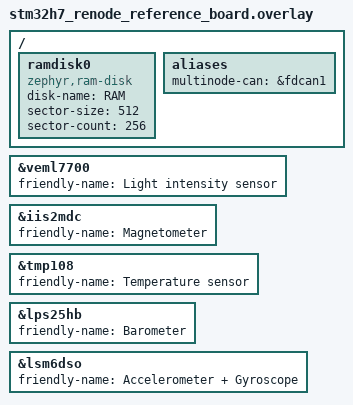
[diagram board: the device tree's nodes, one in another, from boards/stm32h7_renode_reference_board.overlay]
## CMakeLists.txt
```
# Copyright (c) 2026 Antmicro <www.antmicro.com>
# SPDX-License-Identifier: Apache-2.0

cmake_minimum_required(VERSION 3.20)
find_package(Zephyr REQUIRED HINTS $ENV{ZEPHYR_BASE})

project(renode_demo LANGUAGES C)

target_sources(app PRIVATE src/potentiometer.c src/flash_store.c)

target_sources_ifdef(CONFIG_DEMO_USB app PRIVATE src/usbdev.c)
target_sources_ifdef(CONFIG_DEMO_MULTINODE app PRIVATE src/multinode.c)
target_sources_ifdef(CONFIG_DEMO_MULTINODE_ETH app PRIVATE src/multinode_eth.c)
target_sources_ifdef(CONFIG_DEMO_MULTINODE_CAN app PRIVATE src/multinode_can.c)
```

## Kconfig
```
# Copyright (c) 2026 Antmicro <www.antmicro.com>
# SPDX-License-Identifier: Apache-2.0

menu "Demo options"

config DEMO_FLASH_STORE_MSG_BUF_SIZE
	int "Maximum flash_store message size"
	default 128
	help
	  Maximum size of custom message saved to flash storage.

config DEMO_USB
	bool "USB device shell"
	select USB_DEVICE_STACK_NEXT
	select USBD_MSC_CLASS
	help
	  Enable USB device shell.

if DEMO_USB

if LOG

choice USBD_LOG_LEVEL_CHOICE
	default USBD_LOG_LEVEL_WRN

endchoice

choice USBD_MSC_LOG_LEVEL_CHOICE
	default USBD_MSC_LOG_LEVEL_OFF

endchoice

endif # LOG

config DEMO_USB_MAX_POWER
	int "USB device bMaxPower value"
	default 125
	range 0 250
	help
	  bMaxPower value in the usb device configuration in 2 mA units.

endif # DEMO_USB

config DEMO_MULTINODE
	bool "Multinode demo shell"
	default y
	help
	  Enable multinode demo shell.

if DEMO_MULTINODE

config DEMO_MULTINODE_ETH
	bool "Ethernet backend"
	default y
	select NETWORKING
	select NET_IPV4
	select NET_UDP
	select NET_SOCKETS
	select NET_L2_ETHERNET
	help
	  Enable ethernet backend.

if DEMO_MULTINODE_ETH

menu "Network options"

config DEMO_MULTINODE_ETH_SERVER_IP
	string "Server IP"
	default "10.123.123.1"
	help
	  IPv4 address for server node.

config DEMO_MULTINODE_ETH_SERVER_PORT
	int "Server port"
	range 1 65535
	default 4242
	help
	  Port number for the server.

config DEMO_MULTINODE_ETH_CLIENT_IP
	string "Client IP"
	default "10.123.123.2"
	help
	  IPv4 address for client node.

config DEMO_MULTINODE_ETH_NETMASK
	string "Network mask"
	default "255.255.255.0"
	help
	  Network mask for client and server.

config DEMO_MULTINODE_ETH_LINK_TIMEOUT
	int "Link wait time"
	default 10000
	help
	  How long to wait for link to be up before timing out (in ms).

config DEMO_MULTINODE_ETH_RX_TIMEOUT
	int "Response timeout"
	default 1000
	help
	  How long to wait for response (in ms).

config DEMO_MULTINODE_ETH_RX_BUF_SIZE
	int "RX buffer size"
	default 64
	help
	  Rx buffer size (in bytes).

config DEMO_MULTINODE_ETH_TX_BUF_SIZE
	int "TX buffer size"
	default 64
	help
	  Tx buffer size (in bytes).

endmenu

config DEMO_MULTINODE_ETH_SERVER_THRD_STACK_SIZE
	int "Server thread stack size"
	default 2048

config DEMO_MULTINODE_ETH_SERVER_THRD_PRIO
	int "Server thread priority"
	default 5

endif # DEMO_MULTINODE_ETH

config DEMO_MULTINODE_CAN
	bool "CAN backend"
	default y
	select CAN
	select POLL
	help
	  Enable CAN backend.

if DEMO_MULTINODE_CAN

config DEMO_MULTINODE_CAN_REQ_MSG_ID
	hex "Can Request Message ID"
	default 0x25
	help
	  CAN message ID used by request messages.

config DEMO_MULTINODE_CAN_RESP_MSG_ID
	hex "Can Response Message ID"
	default 0x26
	help
	  CAN message ID used by response messages.

config DEMO_MULTINODE_CAN_RX_QUEUE_SIZE
	int "CAN demo receive queue size"
	default 5
	range 1 256
	help
	  Maximum number of CAN frames in the CAN multinohde demo receive queue.

config DEMO_MULTINODE_CAN_TIMEOUT
	int "Message transfer timeout"
	default 1000
	help
	  How long to wait for messages (in ms).

config DEMO_MULTINODE_CAN_LISTEN_THRD_STACK_SIZE
	int "Listen thread stack size"
	default 512

config DEMO_MULTINODE_CAN_LISTEN_THRD_PRIO
	int "Listen thread priority"
	default 5


endif # DEMO_MULTINODE_CAN

endif # DEMO_MULTINODE

endmenu

source "Kconfig.zephyr"
```

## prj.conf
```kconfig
CONFIG_STD_C23=y
CONFIG_BOOT_BANNER_STRING="Booting STM32H7 Renode Reference Platform Demo"

CONFIG_LOG=y
CONFIG_LOG_PROCESS_THREAD_SLEEP_MS=400
CONFIG_LOG_INFO_COLOR_GREEN=y
CONFIG_LOG_DBG_COLOR_BLUE=y

CONFIG_SHELL=y
CONFIG_SHELL_PROMPT_UART="demo:~$ "

CONFIG_STATS=y

CONFIG_ADC=y

CONFIG_CAN=y
CONFIG_CAN_SHELL=y
CONFIG_CAN_STATS=y

CONFIG_FLASH=y
CONFIG_FLASH_LOG_LEVEL_WRN=y
CONFIG_NVS=y
CONFIG_NVS_LOG_LEVEL_WRN=y
CONFIG_REBOOT=y

CONFIG_NETWORKING=y
CONFIG_NET_SHELL=y
CONFIG_NET_HOSTNAME_ENABLE=y
CONFIG_NET_HOSTNAME_DYNAMIC=y
CONFIG_NET_HOSTNAME="demo"
CONFIG_NET_DHCPV4=y
CONFIG_NET_DHCPV4_SERVER=y
CONFIG_NET_IPV4=y
CONFIG_NET_IPV4_FRAGMENT=y
CONFIG_NET_IPV4_PMTU=y
CONFIG_NET_IPV6=y
CONFIG_NET_BUF_POOL_USAGE=y
CONFIG_NET_STATISTICS=y
CONFIG_NET_SHELL_SHOW_DISABLED_COMMANDS=n

CONFIG_DNS_RESOLVER=y

CONFIG_HWINFO_SHELL=y

CONFIG_I2C=y
CONFIG_I2C_SHELL=y
CONFIG_I2C_BUS_RECOVERY=y

CONFIG_INPUT=y
CONFIG_INPUT_SHELL=y
CONFIG_INPUT_EVENT_DUMP=y

CONFIG_LED=y
CONFIG_LED_SHELL=y

CONFIG_SENSOR=y
CONFIG_SENSOR_SHELL=y
CONFIG_SENSOR_INFO=y
CONFIG_MAIN_STACK_SIZE=2048
CONFIG_SYSTEM_WORKQUEUE_STACK_SIZE=2048
```

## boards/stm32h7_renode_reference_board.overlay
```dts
/ {
	// 128KB ramdisk
	ramdisk0 {
		compatible = "zephyr,ram-disk";
		disk-name = "RAM";
		sector-size = <512>;
		sector-count = <256>;
	};

	aliases {
		multinode-can = &fdcan1;
	};
};

&veml7700 {
	friendly-name = "Light intensity sensor";
};

&iis2mdc {
	friendly-name = "Magnetometer";
};

&tmp108 {
	friendly-name = "Temperature sensor";
};

&lps25hb {
	friendly-name = "Barometer";
};

&lsm6dso {
	friendly-name = "Accelerometer + Gyroscope";
};
```

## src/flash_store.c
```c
/*
 * Copyright (c) 2026 Antmicro <www.antmicro.com>
 * SPDX-License-Identifier: Apache-2.0
 */

#include <stddef.h>
#include <stdint.h>
#include <string.h>
#include <zephyr/kernel.h>
#include <zephyr/device.h>
#include <zephyr/drivers/flash.h>
#include <zephyr/storage/flash_map.h>
#include <zephyr/kvss/nvs.h>
#include <zephyr/shell/shell.h>
#include <zephyr/toolchain.h>
#include <zephyr/sys/util.h>
#include <zephyr/logging/log.h>

LOG_MODULE_REGISTER(flash_store);

#define NVS_PARTITION storage_partition

static struct nvs_fs fs = {
	.flash_device = PARTITION_DEVICE(NVS_PARTITION),
	.offset = PARTITION_OFFSET(NVS_PARTITION),
	.sector_count = 3U,
};

#define DEMO_BOOT_CNT_KEY 1
#define DEMO_MESSAGE_KEY  2

static const char demo_message_default[] = "All your base are belong to us";
static uint8_t buffer[CONFIG_DEMO_FLASH_STORE_MSG_BUF_SIZE] = {0};

static int flash_store_bootcnt_cmd_get(const struct shell *sh, size_t argc, char *argv[]);
static int flash_store_bootcnt_cmd_reset(const struct shell *sh, size_t argc, char *argv[]);
static int flash_store_msg_cmd_read(const struct shell *sh, size_t argc, char *argv[]);
static int flash_store_msg_cmd_write(const struct shell *sh, size_t argc, char *argv[]);

static int bootcnt_write(uint32_t cnt)
{
	int rc;

	LOG_DBG("Setting boot count to %d", cnt);
	rc = nvs_write(&fs, DEMO_BOOT_CNT_KEY, (void *)&cnt, sizeof(cnt));
	if (rc < 0) {
		return rc;
	}

	return 0;
}

static int message_write(const char *str)
{
	int rc;
	size_t msg_len = strlen(str);

	/* Truncate string to fit in buffer */
	msg_len = MIN(msg_len, sizeof(buffer) - 1);
	memcpy(buffer, str, msg_len);
	buffer[msg_len++] = 0;

	LOG_DBG("Writing %d bytes long message to flash", msg_len);

	rc = nvs_write(&fs, DEMO_MESSAGE_KEY, (void *)buffer, msg_len);
	if (rc < 0) {
	}
	return rc;
}

static int demo_flash_init(void)
{
	int rc;
	uint32_t boot_cnt;
	struct flash_pages_info info;

	if (!device_is_ready(fs.flash_device)) {
		LOG_ERR("Flash device %s is not ready", fs.flash_device->name);
		return -ENODEV;
	}

	LOG_DBG("Using flash device '%s' at offset %ld", fs.flash_device->name, fs.offset);

	rc = flash_get_page_info_by_offs(fs.flash_device, fs.offset, &info);
	if (rc) {
		LOG_ERR("Unable to get page info (err=%d)", rc);
		return rc;
	}
	fs.sector_size = info.size;

	LOG_DBG("Page Info - start offset: %ld, size: %zu, index: %d", info.start_offset, info.size,
		info.index);

	rc = nvs_mount(&fs);
	if (rc) {
		LOG_ERR("Failed to mount flash storage (err=%d)", rc);
		return rc;
	}

	/* Check if first boot and set default values if so */
	rc = nvs_read(&fs, DEMO_BOOT_CNT_KEY, (void *)&boot_cnt, sizeof(boot_cnt));
	if (rc > 0) {
		LOG_DBG("Boot counter at %d, incrementing to %d", boot_cnt, boot_cnt + 1);
		++boot_cnt;
	} else {
		LOG_DBG("Boot counter not found, setting to default value");
		boot_cnt = 1;
	}
	rc = bootcnt_write(boot_cnt);
	if (rc < 0) {
		LOG_ERR("Failed to write boot count to flash (err=%d)", rc);
		return rc;
	}

	rc = nvs_read(&fs, DEMO_MESSAGE_KEY, (void *)buffer, sizeof(buffer));
	if (rc <= 0) {
		LOG_DBG("Custom message not found, setting to default value");
		rc = message_write(demo_message_default);
		if (rc < 0) {
			LOG_ERR("Failed to write message to flash (err=%d)", rc);
			return rc;
		}
	}

	return 0;
}

SYS_INIT(demo_flash_init, APPLICATION, 0);

SHELL_STATIC_SUBCMD_SET_CREATE(flash_store_bootcnt_cmds,
			       SHELL_CMD_ARG(get, NULL, SHELL_HELP("Get boot counter.", ""),
					     flash_store_bootcnt_cmd_get, 1, 0),
			       SHELL_CMD_ARG(reset, NULL, SHELL_HELP("Reset boot counter.", ""),
					     flash_store_bootcnt_cmd_reset, 1, 0),
			       SHELL_SUBCMD_SET_END);

static int flash_store_bootcnt_cmd_get(const struct shell *sh, size_t argc, char *argv[])
{
	ARG_UNUSED(argc);
	ARG_UNUSED(argv);

	int rc;
	uint32_t boot_cnt;

	rc = nvs_read(&fs, DEMO_BOOT_CNT_KEY, (void *)&boot_cnt, sizeof(boot_cnt));
	if (rc < 0) {
		shell_error(sh, "Reading boot counter failed (err=%d)", rc);
		return rc;
	}

	shell_print(sh, "Boot counter = %d", boot_cnt);
	return 0;
}

static int flash_store_bootcnt_cmd_reset(const struct shell *sh, size_t argc, char *argv[])
{
	ARG_UNUSED(argc);
	ARG_UNUSED(argv);

	int rc;

	rc = bootcnt_write(0);
	if (rc < 0) {
		shell_error(sh, "Failed to reset boot counter (err=%d)", rc);
		return rc;
	}
	shell_info(sh, "Boot counter reset");
	return 0;
}

SHELL_STATIC_SUBCMD_SET_CREATE(flash_store_message_cmds,
			       SHELL_CMD_ARG(read, NULL, SHELL_HELP("Read saved message.", ""),
					     flash_store_msg_cmd_read, 1, 0),
			       SHELL_CMD_ARG(write, NULL,
					     SHELL_HELP("Write new message.", "MESSAGE"),
					     flash_store_msg_cmd_write, 2, SHELL_OPT_ARG_RAW),
			       SHELL_SUBCMD_SET_END);

static int flash_store_msg_cmd_read(const struct shell *sh, size_t argc, char *argv[])
{
	ARG_UNUSED(argc);
	ARG_UNUSED(argv);

	int rc;

	rc = nvs_read(&fs, DEMO_MESSAGE_KEY, (void *)buffer, sizeof(buffer));
	if (rc < 0) {
		shell_error(sh, "Reading saved message failed (err=%d)", rc);
		return rc;
	}

	shell_print(sh, "Saved message is:\n\"%s\"", buffer);
	return 0;
}

static int flash_store_msg_cmd_write(const struct shell *sh, size_t argc, char *argv[])
{
	ARG_UNUSED(argc);
	ARG_UNUSED(argv);

	int rc;

	rc = message_write(argv[1]);
	if (rc < 0) {
		shell_error(sh, "Writing new message failed (err=%d)", rc);
		return rc;
	}

	shell_info(sh, "New message saved to flash");
	return 0;
}

SHELL_STATIC_SUBCMD_SET_CREATE(flash_store_cmds,
			       SHELL_CMD_ARG(boot_counter, &flash_store_bootcnt_cmds,
					     "Boot counter operations", NULL, 2, 0),
			       SHELL_CMD_ARG(message, &flash_store_message_cmds,
					     "Saved message operations", NULL, 2, 0),
			       SHELL_SUBCMD_SET_END);

SHELL_CMD_REGISTER(flash_store, &flash_store_cmds, "Flash storage commands", NULL);
```

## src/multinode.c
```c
/*
 * Copyright (c) 2026 Antmicro <www.antmicro.com>
 * SPDX-License-Identifier: Apache-2.0
 */

#include "multinode.h"

#include <zephyr/shell/shell.h>

#ifdef CONFIG_DEMO_MULTINODE_ETH
SHELL_STATIC_SUBCMD_SET_CREATE(sub_multinode_eth_server_cmds,
			       SHELL_CMD_ARG(start, nullptr, "Start multinode server",
					     multinode_eth_server_start, 1, 0),
			       SHELL_CMD_ARG(stop, nullptr, "Stop multinode server",
					     multinode_eth_server_stop, 1, 0),
			       SHELL_SUBCMD_SET_END);

SHELL_STATIC_SUBCMD_SET_CREATE(sub_multinode_eth_cmds,
			       SHELL_CMD_ARG(server, &sub_multinode_eth_server_cmds, "Server mode",
					     nullptr, 2, 0),
			       SHELL_CMD_ARG(client, nullptr, "Client mode", multinode_eth_client,
					     1, 0),
			       SHELL_SUBCMD_SET_END);
#endif // CONFIG_DEMO_MULTINODE_ETH

#ifdef CONFIG_DEMO_MULTINODE_CAN
SHELL_STATIC_SUBCMD_SET_CREATE(sub_multinode_can_listen_cmds,
			       SHELL_CMD_ARG(start, nullptr, "Start listening for CAN messages",
					     multinode_can_listen_start, 1, 0),
			       SHELL_CMD_ARG(stop, nullptr, "Stop listening for CAN messages",
					     multinode_can_listen_stop, 1, 0),
			       SHELL_SUBCMD_SET_END);

SHELL_STATIC_SUBCMD_SET_CREATE(sub_multinode_can_cmds,
			       SHELL_CMD_ARG(listen, &sub_multinode_can_listen_cmds, "Listen mode",
					     nullptr, 2, 0),
			       SHELL_CMD_ARG(send, nullptr, "Send mode", multinode_can_send, 1, 0),
			       SHELL_SUBCMD_SET_END);
#endif // CONFIG_DEMO_MULTINODE_CAN

SHELL_STATIC_SUBCMD_SET_CREATE(sub_multinode_cmds,
#ifdef CONFIG_DEMO_MULTINODE_ETH
			       SHELL_CMD_ARG(eth, &sub_multinode_eth_cmds,
					     "Multinode demo over ethernet", nullptr, 1, 0),
#endif // CONFIG_DEMO_MULTINODE_ETH
#ifdef CONFIG_DEMO_MULTINODE_CAN
			       SHELL_CMD_ARG(can, &sub_multinode_can_cmds,
					     "Multinode demo over CAN", nullptr, 1, 0),
#endif // CONFIG_DEMO_MULTINODE_CAN
			       SHELL_SUBCMD_SET_END);

SHELL_CMD_REGISTER(multinode, &sub_multinode_cmds, "Multinode demo commands", NULL);
```

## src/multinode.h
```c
/*
 * Copyright (c) 2026 Antmicro <www.antmicro.com>
 * SPDX-License-Identifier: Apache-2.0
 */

#ifndef _MULTINODE_H
#define _MULTINODE_H

#include <zephyr/shell/shell.h>

#ifdef CONFIG_DEMO_MULTINODE_ETH
int multinode_eth_server_start(const struct shell *sh, size_t argc, char *argv[]);
int multinode_eth_server_stop(const struct shell *sh, size_t argc, char *argv[]);
int multinode_eth_client(const struct shell *sh, size_t argc, char *argv[]);
#endif // CONFIG_DEMO_MULTINODE_ETH

#ifdef CONFIG_DEMO_MULTINODE_CAN
int multinode_can_listen_start(const struct shell *sh, size_t argc, char *argv[]);
int multinode_can_listen_stop(const struct shell *sh, size_t argc, char *argv[]);
int multinode_can_send(const struct shell *sh, size_t argc, char *argv[]);
#endif // CONFIG_DEMO_MULTINODE_CAN

#endif // _MULTINODE_H
```

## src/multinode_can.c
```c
/*
 * Copyright (c) 2026 Antmicro <www.antmicro.com>
 * SPDX-License-Identifier: Apache-2.0
 */

#include "multinode.h"

#include <stdint.h>
#include <string.h>

#include <zephyr/device.h>
#include <zephyr/devicetree.h>
#include <zephyr/devicetree/can.h>
#include <zephyr/drivers/can.h>
#include <zephyr/kernel.h>
#include <zephyr/logging/log.h>
#include <zephyr/shell/shell.h>
#include <zephyr/sys/atomic.h>
#include <zephyr/sys/util.h>
#include <zephyr/sys/util_macro.h>
#include <zephyr/toolchain.h>

LOG_MODULE_REGISTER(multinode_can);

BUILD_ASSERT(CONFIG_DEMO_MULTINODE_CAN_REQ_MSG_ID <= CAN_STD_ID_MASK, "CAN filter ID out of range");
BUILD_ASSERT(CONFIG_DEMO_MULTINODE_CAN_RESP_MSG_ID <= CAN_STD_ID_MASK,
	     "CAN filter ID out of range");

#define CAN_DEVICE DT_ALIAS(multinode_can)

const static struct device *dev = DEVICE_DT_GET(CAN_DEVICE);

const static uint32_t max_bitrate = DT_CAN_TRANSCEIVER_MAX_BITRATE(CAN_DEVICE, 1000000);

const static struct can_filter req_filter = {
	.id = CONFIG_DEMO_MULTINODE_CAN_REQ_MSG_ID,
	.mask = CAN_STD_ID_MASK,
	.flags = 0,
};
static int req_filter_id = -1;
CAN_MSGQ_DEFINE(req_msgq, CONFIG_DEMO_MULTINODE_CAN_RX_QUEUE_SIZE);

const static struct can_filter resp_filter = {
	.id = CONFIG_DEMO_MULTINODE_CAN_RESP_MSG_ID,
	.mask = CAN_STD_ID_MASK,
	.flags = 0,
};
static int resp_filter_id = -1;
CAN_MSGQ_DEFINE(resp_msgq, CONFIG_DEMO_MULTINODE_CAN_RX_QUEUE_SIZE);

#define CAN_CONFIGURED  0
#define CAN_LISTENER_ON 1
#define CAN_SENDER_ON   2

// NOTE: This value is only changed inside shell command handlers (shell thread) so we don't
// have to worry about races.
static int can_state = 0;

static int can_setup(const struct shell *sh)
{
	int rc;

	if (IS_BIT_SET(can_state, CAN_CONFIGURED)) {
		return -EALREADY;
	}

	if (!device_is_ready(dev)) {
		shell_error(sh, "Can device %s not ready", dev->name);
		return -ENODEV;
	}

	LOG_DBG("Setting %s bitrate to %ul", dev->name, max_bitrate);
	rc = can_set_bitrate(dev, max_bitrate);
	if (rc < 0) {
		shell_error(sh, "Failed to set %s device bitrate (err %d)", dev->name, rc);
		return rc;
	}

	LOG_DBG("Setting %s mode to normal", dev->name);
	rc = can_set_mode(dev, CAN_MODE_NORMAL);
	if (rc < 0) {
		shell_error(sh, "Failed to set %s device mode (err %d)", dev->name, rc);
		return rc;
	}

	rc = can_start(dev);
	if (rc < 0) {
		shell_error(sh, "Failed to start %s interface (err %d)", dev->name, rc);
		return rc;
	}

	WRITE_BIT(can_state, CAN_CONFIGURED, 1);
	shell_print(sh, "Configured %s interface", dev->name);

	return rc;
}

static int can_shutdown(const struct shell *sh)
{
	if (!IS_BIT_SET(can_state, CAN_CONFIGURED)) {
		return -EALREADY;
	}
	if (FIELD_GET(GENMASK(CAN_SENDER_ON, CAN_LISTENER_ON), can_state)) {
		return 0;
	}

	can_stop(dev);
	can_state = 0;

	shell_print(sh, "Stopped %s interface", dev->name);

	return 0;
}

static void listener_worker(void *a1, void *a2, void *a3)
{
	ARG_UNUSED(a1);
	ARG_UNUSED(a2);
	ARG_UNUSED(a3);

	struct can_frame rx_frame, tx_frame = {.id = CONFIG_DEMO_MULTINODE_CAN_RESP_MSG_ID,
					       .dlc = can_bytes_to_dlc(sizeof(uint64_t)),
					       .flags = 0};
	int rc;
	for (;;) {
		k_msgq_get(&req_msgq, &rx_frame, K_FOREVER);
		if (can_dlc_to_bytes(rx_frame.dlc) != 8) {
			LOG_ERR("malformed message from %d", rx_frame.id);
			continue;
		}

		LOG_INF("incoming 'Ping%" PRIu64 "'", (uint64_t)(*rx_frame.data));

		memcpy(tx_frame.data, rx_frame.data, 8);
		rc = can_send(dev, &tx_frame, K_MSEC(CONFIG_DEMO_MULTINODE_CAN_TIMEOUT), nullptr,
			      nullptr);

		LOG_INF("response 'Pong%" PRIu64 "'", (uint64_t)(*tx_frame.data));
	}
}
K_THREAD_DEFINE(listener_thrd, CONFIG_DEMO_MULTINODE_CAN_LISTEN_THRD_STACK_SIZE, listener_worker,
		nullptr, nullptr, nullptr, CONFIG_DEMO_MULTINODE_CAN_LISTEN_THRD_PRIO, 0, 0);

static void send_callback(const struct device *dev, int error, void *data)
{
	ARG_UNUSED(dev);

	if (error) {
		return;
	}
	k_sem_give(data);
}

int multinode_can_listen_start(const struct shell *sh, size_t argc, char **argv)
{
	int rc;

	if (IS_BIT_SET(can_state, CAN_LISTENER_ON)) {
		shell_error(sh, "Listener on %s already enabled", dev->name);
		return -EALREADY;
	}

	rc = can_setup(sh);
	if (rc && rc != -EALREADY) {
		return rc;
	}

	LOG_DBG("Enabling request filter");
	req_filter_id = can_add_rx_filter_msgq(dev, &req_msgq, &req_filter);
	if (req_filter_id < 0) {
		shell_error(sh, "Failed to enable request message filter (%d)", req_filter_id);
		return req_filter_id;
	}

	WRITE_BIT(can_state, CAN_LISTENER_ON, 1);
	shell_print(sh, "CAN listener started on %s", dev->name);

	return rc;
}

int multinode_can_listen_stop(const struct shell *sh, size_t argc, char **argv)
{
	int rc;

	if (!IS_BIT_SET(can_state, CAN_LISTENER_ON)) {
		shell_error(sh, "Listener on %s already disabled", dev->name);
		return -EALREADY;
	}

	LOG_DBG("Removing request filter");
	can_remove_rx_filter(dev, req_filter_id);
	req_filter_id = -1;

	WRITE_BIT(can_state, CAN_LISTENER_ON, 0);
	shell_print(sh, "CAN listener stopped on %s", dev->name);

	rc = can_shutdown(sh);
	if (rc && rc != -EALREADY) {
		shell_error(sh, "Interface %s already shutdown", dev->name);
		return rc;
	}

	return rc;
}

int multinode_can_send(const struct shell *sh, size_t argc, char **argv)
{
	int rc;
	int64_t now;
	struct can_frame rx_frame, tx_frame = {.id = CONFIG_DEMO_MULTINODE_CAN_REQ_MSG_ID,
					       .dlc = can_bytes_to_dlc(sizeof(uint64_t)),
					       .flags = 0};
	struct k_sem tx_sem;

	rc = can_setup(sh);

	LOG_DBG("Enabling response filter");
	resp_filter_id = can_add_rx_filter_msgq(dev, &resp_msgq, &resp_filter);
	if (resp_filter_id < 0) {
		shell_error(sh, "Failed to enable response message filter (%d)", resp_filter_id);
		return resp_filter_id;
	}
	WRITE_BIT(can_state, CAN_SENDER_ON, 1);

	k_sem_init(&tx_sem, 0, 1);

	for (uint64_t i = 0; i < 4; ++i) {
		memcpy(tx_frame.data, &i, 8);

		shell_print(sh, "send 'Ping%" PRIu64 "'", i);

		now = k_uptime_get();
		rc = can_send(dev, &tx_frame, K_MSEC(CONFIG_DEMO_MULTINODE_CAN_TIMEOUT),
			      send_callback, &tx_sem);
		if (rc < 0 || (rc = k_sem_take(&tx_sem, K_MSEC(CONFIG_DEMO_MULTINODE_CAN_TIMEOUT -
							       (k_uptime_get() - now))))) {
			shell_error(sh, "Sending message failed (err %d)", rc);
			break;
		}

		rc = k_msgq_get(&resp_msgq, &rx_frame,
				K_MSEC(CONFIG_DEMO_MULTINODE_CAN_TIMEOUT - (k_uptime_get() - now)));
		if (rc < 0) {
			shell_error(sh, "Getting response failed (err=%d)", rc);
			break;
		}

		shell_print(sh, "resp 'Pong%" PRIu64 "' (elapsed %" PRIi64 "ms)",
			    (uint64_t)(*rx_frame.data), k_uptime_delta(&now));

		k_sleep(K_SECONDS(1));
	}

	LOG_DBG("Removing response filter");
	can_remove_rx_filter(dev, resp_filter_id);
	resp_filter_id = -1;

	WRITE_BIT(can_state, CAN_SENDER_ON, 0);
	rc |= can_shutdown(sh);

	return rc;
}
```

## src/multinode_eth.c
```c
/*
 * Copyright (c) 2026 Antmicro <www.antmicro.com>
 * SPDX-License-Identifier: Apache-2.0
 */

#include "multinode.h"

#include <stddef.h>
#include <stdint.h>
#include <stdio.h>
#include <string.h>

#include <zephyr/kernel.h>
#include <zephyr/logging/log.h>
#include <zephyr/net/net_if.h>
#include <zephyr/net/net_ip.h>
#include <zephyr/net/socket.h>
#include <zephyr/net/socket_poll.h>
#include <zephyr/shell/shell.h>
#include <zephyr/sys/atomic.h>
#include <zephyr/sys/util.h>
#include <zephyr/sys/util_macro.h>
#include <zephyr/toolchain.h>

LOG_MODULE_REGISTER(multinode_eth);

#define LINK_UP_TIMEOUT 10000
#define LINK_UP_CHECK   100
#define PING_COUNT      4

#define MAGIC       "MNODE"
#define MSG_HELLO   MAGIC "Hello"
#define MSG_PING    MAGIC "Ping"
#define MSG_PONG    MAGIC "Pong"
#define MSG_GOODBYE MAGIC "Bye"

#define MSG_OFFSET(msg) ((msg) + sizeof(MAGIC) - 1)

static K_TIMER_DEFINE(wait_link_up_timer, NULL, NULL);

static K_SEM_DEFINE(multinode_mode, 1, 1);

static K_EVENT_DEFINE(server_evt);
#define SERVER_EVT_START    BIT(0)
#define SERVER_EVT_RUNNING  BIT(1)
#define SERVER_EVT_STOP     BIT(2)
#define SERVER_EVT_SHUTDOWN BIT(3)

static char recv_buf[CONFIG_DEMO_MULTINODE_ETH_RX_BUF_SIZE];
static char send_buf[CONFIG_DEMO_MULTINODE_ETH_TX_BUF_SIZE];
static char ip_buf[NET_IPV4_ADDR_LEN];
static int sock;

static int wait_link_up(const struct shell *sh, struct net_if *iface)
{
	int steps = 0;

	(void)net_if_up(iface);

	if (net_if_is_up(iface)) {
		return 0;
	}

	shell_fprintf_normal(sh, "Waiting for link up");

	k_timer_start(&wait_link_up_timer, K_MSEC(LINK_UP_TIMEOUT), K_NO_WAIT);
	while (!net_if_is_up(iface)) {
		if (k_timer_status_get(&wait_link_up_timer) > 0) {
			shell_print(sh, " Timeout!");
			return -ETIMEDOUT;
		}

		k_sleep(K_MSEC(LINK_UP_CHECK));
		if (++steps == DIV_ROUND_UP(1000, LINK_UP_CHECK)) {
			shell_fprintf_normal(sh, ".");
			steps = 0;
		}
	}

	shell_print(sh, " done");
	return 0;
}

static int iface_addr_set(const struct shell *sh, const char *ip_str)
{
	struct net_if *iface = net_if_get_default();
	struct net_if *found = nullptr;
	struct in_addr addr, netmask;
	int rc;

	if (iface == nullptr) {
		return -ENODEV;
	}

	rc = wait_link_up(sh, iface);
	if (rc) {
		return rc;
	}

	if (zsock_inet_pton(AF_INET, ip_str, &addr) != 1) {
		return -EINVAL;
	}

	if (net_if_ipv4_addr_lookup(&addr, &found) == nullptr) {
		if (net_if_ipv4_addr_add(iface, &addr, NET_ADDR_MANUAL, 0) == nullptr) {
			return -EADDRNOTAVAIL;
		}
	}

	if (zsock_inet_pton(AF_INET, CONFIG_DEMO_MULTINODE_ETH_NETMASK, &netmask) != 1) {
		return -EINVAL;
	}

	if (!net_if_ipv4_set_netmask_by_addr(iface, &addr, &netmask)) {
		return -EADDRNOTAVAIL;
	}

	return 0;
}

static void iface_addr_rm(const char *ip_str)
{
	struct net_if *iface;
	struct in_addr addr;

	if (zsock_inet_pton(AF_INET, ip_str, &addr) != 1) {
		return;
	}

	if (net_if_ipv4_addr_lookup(&addr, &iface) != nullptr) {
		net_if_ipv4_addr_rm(iface, &addr);
	}
}

static int client_send(int sock, const struct sockaddr_in *const dst, const char *data,
		       size_t data_len, char *recv_buf, size_t recv_size)
{
	struct zsock_pollfd pfd = {.fd = sock, .events = ZSOCK_POLLIN};

	if (zsock_sendto(sock, send_buf, data_len, 0, (struct sockaddr *)dst, sizeof(*dst)) < 0) {
		return -errno;
	}

	if (zsock_poll(&pfd, 1, CONFIG_DEMO_MULTINODE_ETH_RX_TIMEOUT) <= 0) {
		return -ETIMEDOUT;
	}

	data_len = zsock_recv(sock, recv_buf, recv_size, 0);
	if (data_len <= 0) {
		return -EIO;
	}
	recv_buf[data_len] = 0;

	return data_len;
}

static void server_worker(void *a1, void *a2, void *a3)
{
	ARG_UNUSED(a1);
	ARG_UNUSED(a2);
	ARG_UNUSED(a3);

	struct sockaddr_in bind_addr = {.sin_family = AF_INET,
					.sin_addr.s_addr = htonl(INADDR_ANY),
					.sin_port = htons(CONFIG_DEMO_MULTINODE_ETH_SERVER_PORT)};

	/* Start in shutdown */
	k_event_set(&server_evt, SERVER_EVT_SHUTDOWN);

	for (;;) {
		k_event_wait(&server_evt, SERVER_EVT_START, false, K_FOREVER);

		sock = zsock_socket(AF_INET, SOCK_DGRAM, IPPROTO_UDP);
		if (sock < 0) {
			LOG_ERR("socket creation failed (err=%d)", errno);
			k_event_set(&server_evt, SERVER_EVT_SHUTDOWN);
			continue;
		}

		if (zsock_bind(sock, (struct sockaddr *)&bind_addr, sizeof(bind_addr)) < 0) {
			LOG_ERR("binding failed (err=%d)", errno);
			k_event_set(&server_evt, SERVER_EVT_SHUTDOWN);
			continue;
		}

		k_event_set(&server_evt, SERVER_EVT_RUNNING);

		do {
			struct sockaddr_in peer = {0};
			socklen_t peer_len = sizeof(peer);
			struct zsock_pollfd pfd = {
				.fd = sock,
				.events = ZSOCK_POLLIN,
			};
			size_t msg_len;

			if (zsock_poll(&pfd, 1, 500) <= 0) {
				continue;
			}

			msg_len = zsock_recvfrom(sock, recv_buf, sizeof(recv_buf) - 1, 0,
						 (struct sockaddr *)&peer, &peer_len);
			if (msg_len <= 0) {
				continue;
			}

			recv_buf[msg_len] = 0;
			LOG_INF("incoming '%s'", MSG_OFFSET(recv_buf));

			zsock_inet_ntop(AF_INET, &peer.sin_addr, ip_buf, sizeof(ip_buf));

			size_t len = 0;
			if (strncmp(recv_buf, MSG_HELLO, strlen(MSG_HELLO)) == 0) {
				len = snprintf(send_buf, sizeof(send_buf), "%s %s", MSG_HELLO,
					       CONFIG_DEMO_MULTINODE_ETH_SERVER_IP);
			} else if (strncmp(recv_buf, MSG_PING, strlen(MSG_PING)) == 0) {
				len = snprintf(send_buf, sizeof(send_buf), "%s%s", MSG_PONG,
					       MSG_OFFSET(recv_buf) + 4);
			} else if (strncmp(recv_buf, MSG_GOODBYE, strlen(MSG_GOODBYE)) == 0) {
				len = snprintf(send_buf, sizeof(send_buf), "%s %s", MSG_GOODBYE,
					       CONFIG_DEMO_MULTINODE_ETH_SERVER_IP);
			} else {
				LOG_WRN("unknown message format, ignoring");
				continue;
			}
			zsock_sendto(sock, send_buf, len, 0, (struct sockaddr *)&peer, peer_len);
			LOG_INF("response '%s'", MSG_OFFSET(send_buf));

		} while (!k_event_test(&server_evt, SERVER_EVT_STOP));

		zsock_close(sock);
		k_event_set(&server_evt, SERVER_EVT_SHUTDOWN);
	}
}

K_THREAD_DEFINE(server_thrd, CONFIG_DEMO_MULTINODE_ETH_SERVER_THRD_STACK_SIZE, server_worker,
		nullptr, nullptr, nullptr, CONFIG_DEMO_MULTINODE_ETH_SERVER_THRD_PRIO, 0, 0);

int multinode_eth_server_start(const struct shell *sh, size_t argc, char *argv[])
{
	int evt = 0;
	int rc;

	if (k_event_test(&server_evt, SERVER_EVT_START | SERVER_EVT_RUNNING)) {
		shell_error(sh, "Server already running");
		rc = -EINVAL;
		goto _server_cmd_mode_give;
	}

	if (k_sem_take(&multinode_mode, K_NO_WAIT)) {
		shell_error(sh, "Can't run in server and client mode at the same time");
		rc = -ENOTSUP;
		goto _server_cmd_mode_give;
	}

	rc = iface_addr_set(sh, CONFIG_DEMO_MULTINODE_ETH_SERVER_IP);
	if (rc) {
		shell_error(sh, "Failed to setup network interface (err=%d)", rc);
		goto _server_cmd_mode_give;
	}

	k_event_set(&server_evt, SERVER_EVT_START);

	evt = k_event_wait(&server_evt, SERVER_EVT_RUNNING | SERVER_EVT_SHUTDOWN, false, K_FOREVER);
	if (IS_BIT_SET(evt, SERVER_EVT_SHUTDOWN)) {
		shell_error(sh, "Failed to start server");
		rc = -ENODEV;
		goto _server_cmd_mode_give;
	}

	shell_print(sh, "Server started on %s:%d", CONFIG_DEMO_MULTINODE_ETH_SERVER_IP,
		    CONFIG_DEMO_MULTINODE_ETH_SERVER_PORT);

	return 0;

_server_cmd_mode_give:
	k_sem_give(&multinode_mode);

	return rc;
}

int multinode_eth_server_stop(const struct shell *sh, size_t argc, char *argv[])
{
	if (k_event_test(&server_evt, SERVER_EVT_STOP | SERVER_EVT_SHUTDOWN)) {
		shell_error(sh, "Server not running");
		return -EINVAL;
	}

	k_event_set(&server_evt, SERVER_EVT_STOP);

	shell_print(sh, "Stopping multinode server...");

	k_event_wait(&server_evt, SERVER_EVT_SHUTDOWN, false, K_FOREVER);
	iface_addr_rm(CONFIG_DEMO_MULTINODE_ETH_SERVER_IP);

	k_sem_give(&multinode_mode);
	shell_print(sh, "Done");

	return 0;
}

int multinode_eth_client(const struct shell *sh, size_t argc, char *argv[])
{
	ARG_UNUSED(argc);
	ARG_UNUSED(argv);

	int rc = 0;
	size_t len;

	if (k_sem_take(&multinode_mode, K_NO_WAIT)) {
		shell_error(sh, "Can't run in server and client mode at the same time");
		return -ENOTSUP;
	}

	rc = iface_addr_set(sh, CONFIG_DEMO_MULTINODE_ETH_CLIENT_IP);
	if (rc) {
		shell_error(sh, "Failed to setup network interface (err=%d)", rc);
		goto _cmd_client_mode_give;
	}

	sock = zsock_socket(AF_INET, SOCK_DGRAM, IPPROTO_UDP);
	if (sock < 0) {
		rc = -errno;
		shell_error(sh, "Socket creation failed (err=%d)", rc);
		goto _cmd_client_addr_rm;
	}

	struct sockaddr_in dst = {.sin_family = AF_INET,
				  .sin_port = htons(CONFIG_DEMO_MULTINODE_ETH_SERVER_PORT)};
	if (zsock_inet_pton(AF_INET, CONFIG_DEMO_MULTINODE_ETH_SERVER_IP, &dst.sin_addr) != 1) {
		rc = -EINVAL;
		shell_error(sh, "Failed to parse server ip %s",
			    CONFIG_DEMO_MULTINODE_ETH_SERVER_IP);
		goto _cmd_client_sock_close;
	};

	len = snprintf(send_buf, sizeof(send_buf), "%s %s", MSG_HELLO,
		       CONFIG_DEMO_MULTINODE_ETH_CLIENT_IP);

	shell_print(sh, "send '%s'", MSG_OFFSET(send_buf));
	rc = client_send(sock, &dst, send_buf, len, recv_buf, sizeof(recv_buf) - 1);
	if (rc < 0) {
		shell_error(sh, "Sending message failed (err=%d)", rc);
		goto _cmd_client_sock_close;
	}
	shell_print(sh, "resp '%s'", MSG_OFFSET(recv_buf));

	for (int i = 0; i <= PING_COUNT; ++i) {
		len = snprintf(send_buf, sizeof(send_buf), "%s%d", MSG_PING, i);
		int64_t now = k_uptime_get();

		shell_print(sh, "send '%s'", MSG_OFFSET(send_buf));
		rc = client_send(sock, &dst, send_buf, len, recv_buf, sizeof(recv_buf) - 1);
		if (rc < 0) {
			shell_error(sh, "Sending message failed (err=%d)", rc);
			goto _cmd_client_sock_close;
		}
		shell_print(sh, "resp '%s' (elapsed %" PRIi64 "ms)", MSG_OFFSET(recv_buf),
			    k_uptime_delta(&now));
		k_sleep(K_SECONDS(1));
	}

	len = snprintf(send_buf, sizeof(send_buf), "%s %s", MSG_GOODBYE,
		       CONFIG_DEMO_MULTINODE_ETH_CLIENT_IP);

	shell_print(sh, "send '%s'", MSG_OFFSET(send_buf));
	rc = client_send(sock, &dst, send_buf, len, recv_buf, sizeof(recv_buf) - 1);
	if (rc < 0) {
		shell_error(sh, "Sending message failed (err=%d)", rc);
		goto _cmd_client_sock_close;
	}
	shell_print(sh, "resp '%s'", MSG_OFFSET(recv_buf));

_cmd_client_sock_close:
	zsock_close(sock);

_cmd_client_addr_rm:
	iface_addr_rm(CONFIG_DEMO_MULTINODE_ETH_CLIENT_IP);

_cmd_client_mode_give:
	k_sem_give(&multinode_mode);

	return rc;
}
```

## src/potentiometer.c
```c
/*
 * Copyright (c) 2026 Antmicro <www.antmicro.com>
 * SPDX-License-Identifier: Apache-2.0
 */

#include <stdint.h>
#include <zephyr/toolchain.h>
#include <zephyr/shell/shell.h>
#include <zephyr/kernel.h>
#include <zephyr/drivers/adc.h>
#include <zephyr/devicetree.h>
#include <zephyr/device.h>
#include <zephyr/sys/atomic.h>
#include <zephyr/logging/log.h>

LOG_MODULE_REGISTER(pot);

#if !DT_NODE_EXISTS(DT_PATH(zephyr_user)) || !DT_NODE_HAS_PROP(DT_PATH(zephyr_user), io_channels)
#error "Missing potentiometer channel definition"
#endif

static const struct adc_dt_spec pot_channel = ADC_DT_SPEC_GET_BY_IDX(DT_PATH(zephyr_user), 0);

K_EVENT_DEFINE(pot_dump_evt);
#define POT_DUMP_ENABLE BIT(0)

struct pot_value {
	int32_t raw;
	int32_t mv;
};

static int pot_cmd_read(const struct shell *sh, size_t argc, char *argv[]);
static int pot_cmd_dump(const struct shell *sh, size_t argc, char *argv[]);

static int pot_read(struct pot_value *reading)
{
	static uint32_t pot_buffer;
	static const struct adc_sequence pot_sequence = {
		.buffer = &pot_buffer,
		.buffer_size = sizeof(pot_buffer),
		.channels = BIT(pot_channel.channel_id),
		.resolution = pot_channel.resolution,
	};
	int err = 0;

	if (!adc_is_ready_dt(&pot_channel)) {
		LOG_ERR("ADC device %s not ready", pot_channel.dev->name);
		return -ENODEV;
	}

	err = adc_read_dt(&pot_channel, &pot_sequence);
	if (err) {
		LOG_ERR("ADC read failed (err=%d)", err);
		return err;
	};

	reading->raw = pot_buffer;
	reading->mv = pot_buffer;

	err = adc_raw_to_millivolts_dt(&pot_channel, &reading->mv);
	if (err) {
		LOG_WRN_ONCE("Unable to convert ADC raw value to millivolts (err=%d)", err);
		reading->mv = 0;
	}

	return 0;
}

static void pot_dump_worker(void *a1, void *a2, void *a3)
{
	ARG_UNUSED(a1);
	ARG_UNUSED(a2);
	ARG_UNUSED(a3);

	struct pot_value reading;

	for (;;) {
		k_event_wait(&pot_dump_evt, POT_DUMP_ENABLE, false, K_FOREVER);

		if (!pot_read(&reading)) {
			LOG_INF("raw = %" PRId32 ", mV = %" PRId32, reading.raw, reading.mv);
		}

		k_sleep(K_SECONDS(1));
	}
}

K_THREAD_DEFINE(pot_read_worker, 512, pot_dump_worker, NULL, NULL, NULL, 5, 0, 0);

SHELL_STATIC_SUBCMD_SET_CREATE(sub_pot_cmds,
			       SHELL_CMD_ARG(read, NULL, SHELL_HELP("Read current value", ""),
					     pot_cmd_read, 1, 0),
			       SHELL_CMD_ARG(dump, NULL,
					     SHELL_HELP("Enable value dumping", "<on|off>"),
					     pot_cmd_dump, 2, 0),
			       SHELL_SUBCMD_SET_END);

static int pot_cmd_read(const struct shell *sh, size_t argc, char *argv[])
{
	ARG_UNUSED(argc);
	ARG_UNUSED(argv);

	int err;
	struct pot_value reading;

	err = pot_read(&reading);
	if (err) {
		shell_error(sh, "Reading potentiometer value failed (err=%d)", err);
		return err;
	}

	shell_info(sh, "Potentiometer (%s) value: %" PRId32 "mv (raw %" PRId32 ")",
		   pot_channel.dev->name, reading.mv, reading.raw);

	return 0;
}

static int pot_cmd_dump(const struct shell *sh, size_t argc, char *argv[])
{
	bool enable;
	int err = 0;

	enable = shell_strtobool(argv[1], 0, &err);
	if (err) {
		shell_error(sh, "Invalid argument: %s", argv[1]);
		return err;
	}

	if (enable) {
		shell_info(sh, "Potentiometer value dumping enabled");
		k_event_set(&pot_dump_evt, POT_DUMP_ENABLE);
	} else {
		shell_info(sh, "Potentiometer value dumping disabled");
		k_event_clear(&pot_dump_evt, POT_DUMP_ENABLE);
	}

	return 0;
}

SHELL_CMD_REGISTER(pot, &sub_pot_cmds, "Potentiometer commands", NULL);
```

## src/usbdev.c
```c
/*
 * Copyright (c) 2026 Antmicro <www.antmicro.com>
 * SPDX-License-Identifier: Apache-2.0
 */

#include <zephyr/kernel.h>
#include <zephyr/init.h>
#include <zephyr/device.h>
#include <zephyr/devicetree.h>
#include <zephyr/usb/usbd.h>
#include <zephyr/usb/class/usbd_msc.h>
#include <zephyr/shell/shell.h>
#include <zephyr/logging/log.h>
#include <stdint.h>

LOG_MODULE_REGISTER(usbdev);

#define DEMO_VID 0x2fe3
#define DEMO_PID 0x0008

USBD_DEVICE_DEFINE(demo_usbd, DEVICE_DT_GET(DT_NODELABEL(zephyr_udc0)), DEMO_VID, DEMO_PID);

USBD_DESC_LANG_DEFINE(demo_lang);
USBD_DESC_MANUFACTURER_DEFINE(demo_mfr, "Antmicro");
USBD_DESC_PRODUCT_DEFINE(demo_product, "STM32H7 Renode Reference Platform");
USBD_DESC_SERIAL_NUMBER_DEFINE(demo_sn);

USBD_DESC_CONFIG_DEFINE(fs_cfg_desc, "FS Configuration");

static const uint8_t attributes = USB_SCD_SELF_POWERED;

USBD_CONFIGURATION_DEFINE(demo_fs_config, attributes, CONFIG_DEMO_USB_MAX_POWER, &fs_cfg_desc);

USBD_DEFINE_MSC_LUN(ram, "RAM", "Zephyr", "RAMDisk", "0.00");

static int usbdev_cmd_on(const struct shell *sh, size_t argc, char *argv[]);
static int usbdev_cmd_off(const struct shell *sh, size_t argc, char *argv[]);

static int usbd_setup_device(void)
{
	int err;

	err = usbd_add_descriptor(&demo_usbd, &demo_lang);
	if (err) {
		LOG_ERR("Failed to initialize language descriptor (err=%d)", err);
		return err;
	}

	err = usbd_add_descriptor(&demo_usbd, &demo_mfr);
	if (err) {
		LOG_ERR("Failed to initialize manufacturer descriptor (err=%d)", err);
		return err;
	}

	err = usbd_add_descriptor(&demo_usbd, &demo_product);
	if (err) {
		LOG_ERR("Failed to initialize product descriptor (err=%d)", err);
		return err;
	}

	err = usbd_add_descriptor(&demo_usbd, &demo_sn);
	if (err) {
		LOG_ERR("Failed to initialize SN descriptor (err=%d)", err);
		return err;
	}

	err = usbd_add_configuration(&demo_usbd, USBD_SPEED_FS, &demo_fs_config);
	if (err) {
		LOG_ERR("Failed to add Full-Speed configuration (err=%d)", err);
		return err;
	}

	err = usbd_register_all_classes(&demo_usbd, USBD_SPEED_FS, 1, NULL);
	if (err) {
		LOG_ERR("Failed to add register classes (err=%d)", err);
		return err;
	}

	usbd_self_powered(&demo_usbd, attributes & USB_SCD_SELF_POWERED);

	err = usbd_init(&demo_usbd);
	if (err) {
		LOG_ERR("Failed to initialize USB stack (err=%d)", err);
		return err;
	}

	return 0;
}

SYS_INIT(usbd_setup_device, APPLICATION, 0);

SHELL_STATIC_SUBCMD_SET_CREATE(sub_usbdev_cmds,
			       SHELL_CMD_ARG(on, NULL,
					     SHELL_HELP("Enable USB mass-storage device", ""),
					     usbdev_cmd_on, 1, 0),
			       SHELL_CMD_ARG(off, NULL,
					     SHELL_HELP("Disable USB mass-storage device", ""),
					     usbdev_cmd_off, 1, 0),
			       SHELL_SUBCMD_SET_END);

static int usbdev_cmd_on(const struct shell *sh, size_t argc, char *argv[])
{
	int err;

	err = usbd_enable(&demo_usbd);
	if (err) {
		shell_error(sh, "Failed to enable USB device stack");
		return err;
	}

	shell_info(sh, "Enabled USB mass-storage device");

	return 0;
}

static int usbdev_cmd_off(const struct shell *sh, size_t argc, char *argv[])
{
	int err;

	err = usbd_disable(&demo_usbd);
	if (err) {
		shell_error(sh, "Failed to disable USB device stack");
		return err;
	}

	shell_info(sh, "Disabled USB mass-storage device");

	return 0;
}

SHELL_CMD_REGISTER(usbdev, &sub_usbdev_cmds, "USB mass-storage device commands", NULL);
```
